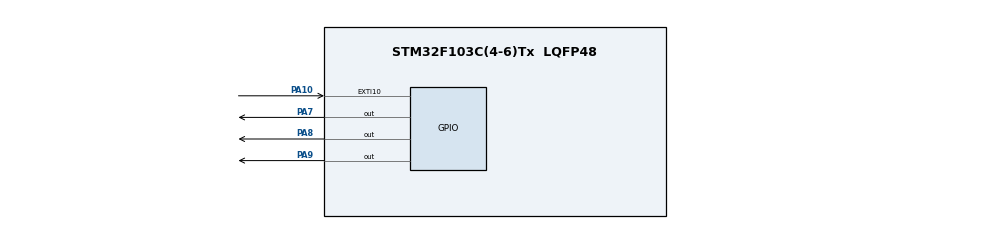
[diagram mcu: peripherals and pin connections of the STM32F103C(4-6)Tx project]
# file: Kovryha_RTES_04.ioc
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Mcu.Family=STM32F1
Mcu.Name=STM32F103C(4-6)Tx
Mcu.Package=LQFP48
NVIC.EXTI15_10_IRQn=true\:0\:0\:false\:true\:true\:1\:true\:true
NVIC.PriorityGroup=NVIC_PRIORITYGROUP_4
NVIC.TIM2_IRQn=true\:0\:0\:false\:true\:true\:2\:true\:true
NVIC.TIM3_IRQn=true\:0\:0\:false\:true\:true\:3\:true\:true
PA10.Signal=GPXTI10
PA7.Signal=GPIO_Output
PA8.Signal=GPIO_Output
PA9.Signal=GPIO_Output
ProjectManager.HeapSize=0x200
ProjectManager.StackSize=0x400
ProjectManager.TargetToolchain=STM32CubeIDE
RCC.APB1Freq_Value=8000000
RCC.APB2Freq_Value=8000000
TIM2.Period=200
TIM2.Prescaler=8000
TIM2.TIM_MasterOutputTrigger=TIM_TRGO_UPDATE
TIM3.Period=100
TIM3.Prescaler=8000
TIM3.TIM_MasterOutputTrigger=TIM_TRGO_UPDATE
VP_SYS_VS_ND.Mode=No_Debug
VP_TIM2_VS_ClockSourceINT.Mode=Internal
VP_TIM3_VS_ClockSourceINT.Mode=Internal
board=custom

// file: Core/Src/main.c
/* USER CODE BEGIN Header */
/**
  ******************************************************************************
  * @file           : main.c
  * @brief          : Main program body
  ******************************************************************************
  * @attention
  *
  * <h2><center>&copy; Copyright (c) 2021 STMicroelectronics.
  * All rights reserved.</center></h2>
  *
  * This software component is licensed by ST under BSD 3-Clause license,
  * the "License"; You may not use this file except in compliance with the
  * License. You may obtain a copy of the License at:
  *                        opensource.org/licenses/BSD-3-Clause
  *
  ******************************************************************************
  */
/* USER CODE END Header */
#include "main.h"

TIM_HandleTypeDef htim2;
TIM_HandleTypeDef htim3;

void SystemClock_Config(void);
static void MX_GPIO_Init(void);
static void MX_TIM2_Init(void);
static void MX_TIM3_Init(void);
static void MX_NVIC_Init(void);

/* USER CODE BEGIN 0 */
 int i = 1;
/* USER CODE END 0 */

int main(void)
{

  /* MCU Configuration--------------------------------------------------------*/

  /* Reset of all peripherals, Initializes the Flash interface and the Systick. */
  HAL_Init();

  /* Configure the system clock */
  SystemClock_Config();

  /* Initialize all configured peripherals */
  MX_GPIO_Init();
  MX_TIM2_Init();
  MX_TIM3_Init();

  /* Initialize interrupts */
  MX_NVIC_Init();
  /* USER CODE BEGIN 2 */
  HAL_TIM_Base_Start_IT (&htim2);
  HAL_TIM_Base_Start_IT (&htim3);
  /* USER CODE END 2 */

  /* Infinite loop */
  while (1)
  {

  }
}

void SystemClock_Config(void)
{
  RCC_OscInitTypeDef RCC_OscInitStruct = {0};
  RCC_ClkInitTypeDef RCC_ClkInitStruct = {0};

  /** Initializes the RCC Oscillators according to the specified parameters
  * in the RCC_OscInitTypeDef structure.
  */
  RCC_OscInitStruct.OscillatorType = RCC_OSCILLATORTYPE_HSI;
  RCC_OscInitStruct.HSIState = RCC_HSI_ON;
  RCC_OscInitStruct.HSICalibrationValue = RCC_HSICALIBRATION_DEFAULT;
  RCC_OscInitStruct.PLL.PLLState = RCC_PLL_NONE;
  if (HAL_RCC_OscConfig(&RCC_OscInitStruct) != HAL_OK)
  {
    Error_Handler();
  }
  /** Initializes the CPU, AHB and APB buses clocks
  */
  RCC_ClkInitStruct.ClockType = RCC_CLOCKTYPE_HCLK|RCC_CLOCKTYPE_SYSCLK
                              |RCC_CLOCKTYPE_PCLK1|RCC_CLOCKTYPE_PCLK2;
  RCC_ClkInitStruct.SYSCLKSource = RCC_SYSCLKSOURCE_HSI;
  RCC_ClkInitStruct.AHBCLKDivider = RCC_SYSCLK_DIV1;
  RCC_ClkInitStruct.APB1CLKDivider = RCC_HCLK_DIV1;
  RCC_ClkInitStruct.APB2CLKDivider = RCC_HCLK_DIV1;

  if (HAL_RCC_ClockConfig(&RCC_ClkInitStruct, FLASH_LATENCY_0) != HAL_OK)
  {
    Error_Handler();
  }
}

/**
  * @brief NVIC Configuration.
  * @retval None
  */
static void MX_NVIC_Init(void)
{
  /* EXTI15_10_IRQn interrupt configuration */
  HAL_NVIC_SetPriority(EXTI15_10_IRQn, 0, 0);
  HAL_NVIC_EnableIRQ(EXTI15_10_IRQn);
  /* TIM2_IRQn interrupt configuration */
  HAL_NVIC_SetPriority(TIM2_IRQn, 0, 0);
  HAL_NVIC_EnableIRQ(TIM2_IRQn);
  /* TIM3_IRQn interrupt configuration */
  HAL_NVIC_SetPriority(TIM3_IRQn, 0, 0);
  HAL_NVIC_EnableIRQ(TIM3_IRQn);
}

static void MX_TIM2_Init(void)
{

  TIM_ClockConfigTypeDef sClockSourceConfig = {0};
  TIM_MasterConfigTypeDef sMasterConfig = {0};

  htim2.Instance = TIM2;
  htim2.Init.Prescaler = 8000;
  htim2.Init.CounterMode = TIM_COUNTERMODE_UP;
  htim2.Init.Period = 200;
  htim2.Init.ClockDivision = TIM_CLOCKDIVISION_DIV1;
  htim2.Init.AutoReloadPreload = TIM_AUTORELOAD_PRELOAD_DISABLE;
  if (HAL_TIM_Base_Init(&htim2) != HAL_OK)
  {
    Error_Handler();
  }
  sClockSourceConfig.ClockSource = TIM_CLOCKSOURCE_INTERNAL;
  if (HAL_TIM_ConfigClockSource(&htim2, &sClockSourceConfig) != HAL_OK)
  {
    Error_Handler();
  }
  sMasterConfig.MasterOutputTrigger = TIM_TRGO_UPDATE;
  sMasterConfig.MasterSlaveMode = TIM_MASTERSLAVEMODE_DISABLE;
  if (HAL_TIMEx_MasterConfigSynchronization(&htim2, &sMasterConfig) != HAL_OK)
  {
    Error_Handler();
  }

}

static void MX_TIM3_Init(void)
{

  TIM_ClockConfigTypeDef sClockSourceConfig = {0};
  TIM_MasterConfigTypeDef sMasterConfig = {0};

  htim3.Instance = TIM3;
  htim3.Init.Prescaler = 8000;
  htim3.Init.CounterMode = TIM_COUNTERMODE_UP;
  htim3.Init.Period = 100;
  htim3.Init.ClockDivision = TIM_CLOCKDIVISION_DIV1;
  htim3.Init.AutoReloadPreload = TIM_AUTORELOAD_PRELOAD_DISABLE;
  if (HAL_TIM_Base_Init(&htim3) != HAL_OK)
  {
    Error_Handler();
  }
  sClockSourceConfig.ClockSource = TIM_CLOCKSOURCE_INTERNAL;
  if (HAL_TIM_ConfigClockSource(&htim3, &sClockSourceConfig) != HAL_OK)
  {
    Error_Handler();
  }
  sMasterConfig.MasterOutputTrigger = TIM_TRGO_UPDATE;
  sMasterConfig.MasterSlaveMode = TIM_MASTERSLAVEMODE_DISABLE;
  if (HAL_TIMEx_MasterConfigSynchronization(&htim3, &sMasterConfig) != HAL_OK)
  {
    Error_Handler();
  }

}

static void MX_GPIO_Init(void)
{
  GPIO_InitTypeDef GPIO_InitStruct = {0};

  /* GPIO Ports Clock Enable */
  __HAL_RCC_GPIOA_CLK_ENABLE();

  /*Configure GPIO pin Output Level */
  HAL_GPIO_WritePin(GPIOA, GPIO_PIN_7|GPIO_PIN_8|GPIO_PIN_9, GPIO_PIN_RESET);

  /*Configure GPIO pins : PA7 PA8 PA9 */
  GPIO_InitStruct.Pin = GPIO_PIN_7|GPIO_PIN_8|GPIO_PIN_9;
  GPIO_InitStruct.Mode = GPIO_MODE_OUTPUT_PP;
  GPIO_InitStruct.Pull = GPIO_NOPULL;
  GPIO_InitStruct.Speed = GPIO_SPEED_FREQ_LOW;
  HAL_GPIO_Init(GPIOA, &GPIO_InitStruct);

  /*Configure GPIO pin : PA10 */
  GPIO_InitStruct.Pin = GPIO_PIN_10;
  GPIO_InitStruct.Mode = GPIO_MODE_IT_RISING;
  GPIO_InitStruct.Pull = GPIO_NOPULL;
  HAL_GPIO_Init(GPIOA, &GPIO_InitStruct);

}

/* USER CODE BEGIN 4 */
void HAL_GPIO_EXTI_Callback (uint16_t GPIO_Pin)
{
	HAL_GPIO_WritePin (GPIOA, GPIO_PIN_7, GPIO_PIN_SET);
	HAL_GPIO_WritePin (GPIOA, GPIO_PIN_8, GPIO_PIN_SET);
}

void HAL_TIM_PeriodElapsedCallback (TIM_HandleTypeDef *htim)
{
	if ((htim->Instance == TIM2) && (HAL_GPIO_ReadPin (GPIOA, GPIO_PIN_9) == GPIO_PIN_RESET))
	{
		HAL_GPIO_TogglePin (GPIOA, GPIO_PIN_7);
	}
	if ((htim->Instance == TIM3) && (HAL_GPIO_ReadPin (GPIOA, GPIO_PIN_9) == GPIO_PIN_RESET))
	{
		HAL_GPIO_TogglePin (GPIOA, GPIO_PIN_8);
	}

}
/* USER CODE END 4 */

void Error_Handler(void)
{
  __disable_irq();
  while (1)
  {
  }
}
